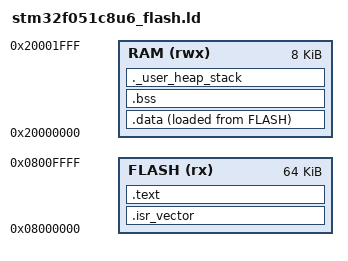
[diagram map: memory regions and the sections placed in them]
/* Define the memory areas */
MEMORY
{
  FLASH (rx) : ORIGIN = 0x08000000, LENGTH = 64K
  RAM (rwx) : ORIGIN = 0x20000000, LENGTH = 8K
}

/* Define the sections */
SECTIONS
{
  .isr_vector :
  {
    . = ALIGN(4);
    KEEP(*(.isr_vector))
    . = ALIGN(4);
  } >FLASH

  .text :
  {
    . = ALIGN(4);
    *(.text*)
    *(.rodata*)
    *(.glue_7)
    *(.glue_7t)
    *(.eh_frame)
    KEEP (*(.init))
    KEEP (*(.fini))
    . = ALIGN(4);
    _etext = .;
  } >FLASH

  _sidata = LOADADDR(.data);

  .data :
  {
    . = ALIGN(4);
    _sdata = .;
    *(.data*)
    . = ALIGN(4);
    _edata = .;
  } >RAM AT> FLASH

  .bss :
  {
    . = ALIGN(4);
    _sbss = .;
    *(.bss*)
    *(COMMON)
    . = ALIGN(4);
    _ebss = .;
  } >RAM

  ._user_heap_stack :
  {
    . = ALIGN(4);
    PROVIDE ( end = . );
    PROVIDE ( _end = . );
    . = . + _Minimum_Stack_Size;
    . = ALIGN(4);
  } >RAM

  _estack = ORIGIN(RAM) + LENGTH(RAM);
}

PROVIDE(_stack = _estack);

_Minimum_Stack_Size = 0x400;    /* 1KB stack size */

